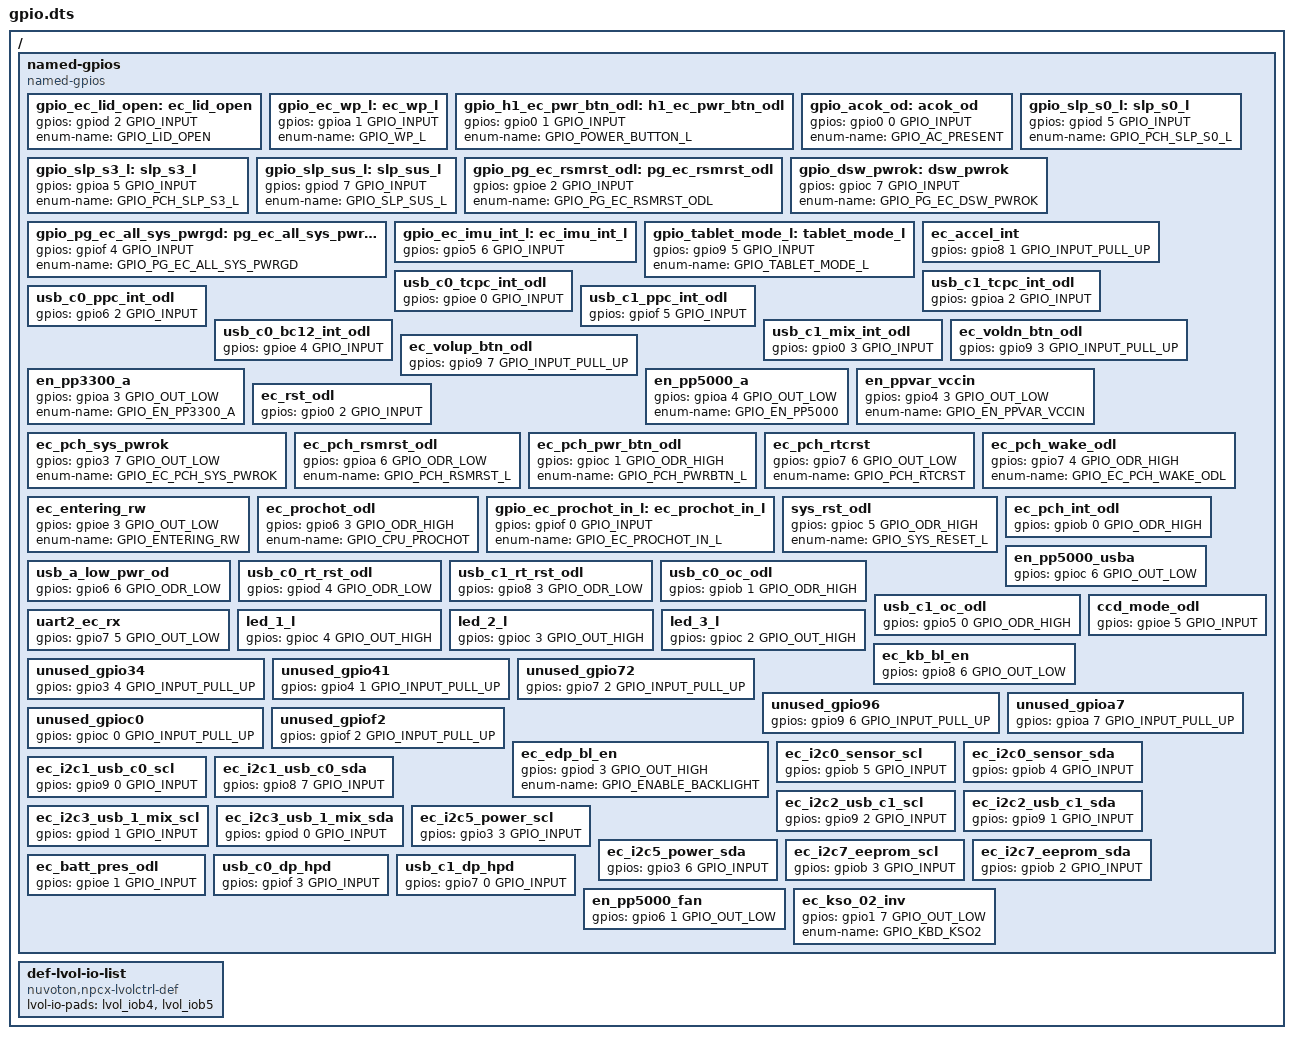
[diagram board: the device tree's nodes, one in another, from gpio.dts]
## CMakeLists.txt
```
# Copyright 2021 The Chromium OS Authors. All rights reserved.
# Use of this source code is governed by a BSD-style license that can be
# found in the LICENSE file.

cmake_minimum_required(VERSION 3.13.1)

find_package(Zephyr REQUIRED HINTS $ENV{ZEPHYR_BASE})
project(delbin)

set(PLATFORM_EC_BOARD "${PLATFORM_EC}/board/delbin" CACHE PATH
  "Path to the platform/ec board directory")
set(PLATFORM_EC_BASEBOARD "${PLATFORM_EC}/baseboard/volteer" CACHE PATH
  "Path to the platform/ec baseboard directory")

# Include board specific header files
zephyr_library_include_directories(
  include
  "${PLATFORM_EC_BASEBOARD}"
  "${PLATFORM_EC_BOARD}")

# Include selected EC source for the baseboard
zephyr_library_sources_ifdef(CONFIG_PLATFORM_EC_POWERSEQ
  "${PLATFORM_EC_BASEBOARD}/power.c")
```

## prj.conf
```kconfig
# Copyright 2021 The Chromium OS Authors. All rights reserved.
# Use of this source code is governed by a BSD-style license that can be
# found in the LICENSE file.

CONFIG_CROS_EC=y
CONFIG_PLATFORM_EC=y
CONFIG_SHIMMED_TASKS=y
CONFIG_I2C=y
CONFIG_PLATFORM_EC_BRINGUP=y

CONFIG_ARM_MPU=y

CONFIG_PLATFORM_EC_VBOOT_EFS2=n

CONFIG_ESPI=y
CONFIG_PLATFORM_EC_ESPI_VW_SLP_S4=y
CONFIG_PLATFORM_EC_ESPI_VW_SLP_S5=y

CONFIG_PLATFORM_EC_EXTPOWER_GPIO=y
CONFIG_PLATFORM_EC_LID_SWITCH=y
CONFIG_PLATFORM_EC_POWER_BUTTON=y

# Power sequencing
CONFIG_AP=y
CONFIG_AP_X86_INTEL_TGL=y
CONFIG_PLATFORM_EC_POWERSEQ=y
CONFIG_PLATFORM_EC_POWERSEQ_RTC_RESET=y
CONFIG_PLATFORM_EC_POWERSEQ_S0IX=y
CONFIG_PLATFORM_EC_POWERSEQ_S4=y
CONFIG_PLATFORM_EC_POWER_SLEEP_FAILURE_DETECTION=y
CONFIG_PLATFORM_EC_THROTTLE_AP=y
CONFIG_PLATFORM_EC_KEYBOARD_COL2_INVERTED=y

# TODO(b/180410072): bringup these features
CONFIG_PLATFORM_EC_BOARD_VERSION_CBI=n
CONFIG_PLATFORM_EC_BOARD_VERSION_GPIO=n
CONFIG_PLATFORM_EC_VBOOT_HASH=n
CONFIG_PLATFORM_EC_VSTORE=n

# Sensors
CONFIG_PLATFORM_EC_MOTIONSENSE=y
CONFIG_PLATFORM_EC_ACCEL_FIFO=y
CONFIG_PLATFORM_EC_ACCEL_INTERRUPTS=y
CONFIG_PLATFORM_EC_DYNAMIC_MOTION_SENSOR_COUNT=y
CONFIG_PLATFORM_EC_GMR_TABLET_MODE=y
CONFIG_PLATFORM_EC_LID_ANGLE=y
CONFIG_PLATFORM_EC_LID_ANGLE_UPDATE=y
CONFIG_PLATFORM_EC_SENSOR_TIGHT_TIMESTAMPS=y
CONFIG_PLATFORM_EC_TABLET_MODE=y
CONFIG_PLATFORM_EC_THERMISTOR=y
CONFIG_PLATFORM_EC_TEMP_SENSOR=y

# Sensor Drivers
CONFIG_PLATFORM_EC_ACCEL_BMA255=y
CONFIG_PLATFORM_EC_ACCELGYRO_BMI260=y
CONFIG_PLATFORM_EC_ACCELGYRO_BMI_COMM_I2C=y

CONFIG_SYSCON=y
```

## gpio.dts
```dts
/* Copyright 2021 The Chromium OS Authors. All rights reserved.
 * Use of this source code is governed by a BSD-style license that can be
 * found in the LICENSE file.
 */

/ {
	named-gpios {
		compatible = "named-gpios";

		gpio_ec_lid_open: ec_lid_open {
			gpios = <&gpiod 2 GPIO_INPUT>;
			enum-name = "GPIO_LID_OPEN";
		};
		gpio_ec_wp_l: ec_wp_l {
			gpios = <&gpioa 1 GPIO_INPUT>;
			enum-name = "GPIO_WP_L";
		};
		gpio_h1_ec_pwr_btn_odl: h1_ec_pwr_btn_odl {
			gpios = <&gpio0 1 GPIO_INPUT>;
			enum-name = "GPIO_POWER_BUTTON_L";
		};
		gpio_acok_od: acok_od {
			gpios = <&gpio0 0 GPIO_INPUT>;
			enum-name = "GPIO_AC_PRESENT";
		};
		gpio_slp_s0_l: slp_s0_l {
			gpios = <&gpiod 5 GPIO_INPUT>;
			enum-name = "GPIO_PCH_SLP_S0_L";
		};
		gpio_slp_s3_l: slp_s3_l {
			gpios = <&gpioa 5 GPIO_INPUT>;
			enum-name = "GPIO_PCH_SLP_S3_L";
		};
		gpio_slp_sus_l: slp_sus_l {
			gpios = <&gpiod 7 GPIO_INPUT>;
			enum-name = "GPIO_SLP_SUS_L";
		};
		gpio_pg_ec_rsmrst_odl: pg_ec_rsmrst_odl {
			gpios = <&gpioe 2 GPIO_INPUT>;
			enum-name = "GPIO_PG_EC_RSMRST_ODL";
		};
		gpio_dsw_pwrok: dsw_pwrok {
			gpios = <&gpioc 7 GPIO_INPUT>;
			enum-name = "GPIO_PG_EC_DSW_PWROK";
		};
		gpio_pg_ec_all_sys_pwrgd: pg_ec_all_sys_pwrgd {
			gpios = <&gpiof 4 GPIO_INPUT>;
			enum-name = "GPIO_PG_EC_ALL_SYS_PWRGD";
		};
		gpio_ec_imu_int_l: ec_imu_int_l {
			gpios = <&gpio5 6 GPIO_INPUT>;
		};
		gpio_tablet_mode_l: tablet_mode_l {
			gpios = <&gpio9 5 GPIO_INPUT>;
			enum-name = "GPIO_TABLET_MODE_L";
		};
		ec_accel_int {
			gpios = <&gpio8 1 GPIO_INPUT_PULL_UP>;
		};
		usb_c0_tcpc_int_odl {
			gpios = <&gpioe 0 GPIO_INPUT>;
		};
		usb_c1_tcpc_int_odl {
			gpios = <&gpioa 2 GPIO_INPUT>;
		};
		usb_c0_ppc_int_odl {
			gpios = <&gpio6 2 GPIO_INPUT>;
		};
		usb_c1_ppc_int_odl {
			gpios = <&gpiof 5 GPIO_INPUT>;
		};
		usb_c0_bc12_int_odl {
			gpios = <&gpioe 4 GPIO_INPUT>;
		};
		usb_c1_mix_int_odl {
			gpios = <&gpio0 3 GPIO_INPUT>;
		};
		ec_voldn_btn_odl {
			gpios = <&gpio9 3 GPIO_INPUT_PULL_UP>;
		};
		ec_volup_btn_odl {
			gpios = <&gpio9 7 GPIO_INPUT_PULL_UP>;
		};
		en_pp3300_a {
			gpios = <&gpioa 3 GPIO_OUT_LOW>;
			enum-name = "GPIO_EN_PP3300_A";
		};
		en_pp5000_a {
			gpios = <&gpioa 4 GPIO_OUT_LOW>;
			enum-name = "GPIO_EN_PP5000";
		};
		en_ppvar_vccin {
			gpios = <&gpio4 3 GPIO_OUT_LOW>;
			enum-name = "GPIO_EN_PPVAR_VCCIN";
		};
		ec_rst_odl {
			gpios = <&gpio0 2 GPIO_INPUT>;
		};
		ec_pch_sys_pwrok {
			gpios = <&gpio3 7 GPIO_OUT_LOW>;
			enum-name = "GPIO_EC_PCH_SYS_PWROK";
		};
		ec_pch_rsmrst_odl {
			gpios = <&gpioa 6 GPIO_ODR_LOW>;
			enum-name = "GPIO_PCH_RSMRST_L";
		};
		ec_pch_pwr_btn_odl {
			gpios = <&gpioc 1 GPIO_ODR_HIGH>;
			enum-name = "GPIO_PCH_PWRBTN_L";
		};
		ec_pch_rtcrst {
			gpios = <&gpio7 6 GPIO_OUT_LOW>;
			enum-name = "GPIO_PCH_RTCRST";
		};
		ec_pch_wake_odl {
			gpios = <&gpio7 4 GPIO_ODR_HIGH>;
			enum-name = "GPIO_EC_PCH_WAKE_ODL";
		};
		ec_entering_rw {
			gpios = <&gpioe 3 GPIO_OUT_LOW>;
			enum-name = "GPIO_ENTERING_RW";
		};
		ec_prochot_odl {
			gpios = <&gpio6 3 GPIO_ODR_HIGH>;
			enum-name = "GPIO_CPU_PROCHOT";
		};
		gpio_ec_prochot_in_l: ec_prochot_in_l {
			gpios = <&gpiof 0 GPIO_INPUT>;
			enum-name = "GPIO_EC_PROCHOT_IN_L";
		};
		sys_rst_odl {
			gpios = <&gpioc 5 GPIO_ODR_HIGH>;
			enum-name = "GPIO_SYS_RESET_L";
		};
		ec_pch_int_odl {
			gpios = <&gpiob 0 GPIO_ODR_HIGH>;
		};
		en_pp5000_usba {
			gpios = <&gpioc 6 GPIO_OUT_LOW>;
		};
		usb_a_low_pwr_od {
			gpios = <&gpio6 6 GPIO_ODR_LOW>;
		};
		usb_c0_rt_rst_odl {
			gpios = <&gpiod 4 GPIO_ODR_LOW>;
		};
		usb_c1_rt_rst_odl {
			gpios = <&gpio8 3 GPIO_ODR_LOW>;
		};
		usb_c0_oc_odl {
			gpios = <&gpiob 1 GPIO_ODR_HIGH>;
		};
		usb_c1_oc_odl {
			gpios = <&gpio5 0 GPIO_ODR_HIGH>;
		};
		uart2_ec_rx {
			gpios = <&gpio7 5 GPIO_OUT_LOW>;
		};
		led_1_l {
			gpios = <&gpioc 4 GPIO_OUT_HIGH>;
		};
		led_2_l {
			gpios = <&gpioc 3 GPIO_OUT_HIGH>;
		};
		led_3_l {
			gpios = <&gpioc 2 GPIO_OUT_HIGH>;
		};
		ccd_mode_odl {
			gpios = <&gpioe 5 GPIO_INPUT>;
		};
		ec_kb_bl_en {
			gpios = <&gpio8 6 GPIO_OUT_LOW>;
		};
		unused_gpio34 {
			gpios = <&gpio3 4 GPIO_INPUT_PULL_UP>;
		};
		unused_gpio41 {
			gpios = <&gpio4 1 GPIO_INPUT_PULL_UP>;
		};
		unused_gpio72 {
			gpios = <&gpio7 2 GPIO_INPUT_PULL_UP>;
		};
		unused_gpio96 {
			gpios = <&gpio9 6 GPIO_INPUT_PULL_UP>;
		};
		unused_gpioa7 {
			gpios = <&gpioa 7 GPIO_INPUT_PULL_UP>;
		};
		unused_gpioc0 {
			gpios = <&gpioc 0 GPIO_INPUT_PULL_UP>;
		};
		unused_gpiof2 {
			gpios = <&gpiof 2 GPIO_INPUT_PULL_UP>;
		};
		ec_edp_bl_en {
			gpios = <&gpiod 3 GPIO_OUT_HIGH>;
			enum-name = "GPIO_ENABLE_BACKLIGHT";
		};
		ec_i2c0_sensor_scl {
			gpios = <&gpiob 5 GPIO_INPUT>;
		};
		ec_i2c0_sensor_sda {
			gpios = <&gpiob 4 GPIO_INPUT>;
		};
		ec_i2c1_usb_c0_scl {
			gpios = <&gpio9 0 GPIO_INPUT>;
		};
		ec_i2c1_usb_c0_sda {
			gpios = <&gpio8 7 GPIO_INPUT>;
		};
		ec_i2c2_usb_c1_scl {
			gpios = <&gpio9 2 GPIO_INPUT>;
		};
		ec_i2c2_usb_c1_sda {
			gpios = <&gpio9 1 GPIO_INPUT>;
		};
		ec_i2c3_usb_1_mix_scl {
			gpios = <&gpiod 1 GPIO_INPUT>;
		};
		ec_i2c3_usb_1_mix_sda {
			gpios = <&gpiod 0 GPIO_INPUT>;
		};
		ec_i2c5_power_scl {
			gpios = <&gpio3 3 GPIO_INPUT>;
		};
		ec_i2c5_power_sda {
			gpios = <&gpio3 6 GPIO_INPUT>;
		};
		ec_i2c7_eeprom_scl {
			gpios = <&gpiob 3 GPIO_INPUT>;
		};
		ec_i2c7_eeprom_sda {
			gpios = <&gpiob 2 GPIO_INPUT>;
		};
		ec_batt_pres_odl {
			gpios = <&gpioe 1 GPIO_INPUT>;
		};
		usb_c0_dp_hpd {
			gpios = <&gpiof 3 GPIO_INPUT>;
		};
		usb_c1_dp_hpd {
			gpios = <&gpio7 0 GPIO_INPUT>;
		};
		en_pp5000_fan {
			gpios = <&gpio6 1 GPIO_OUT_LOW>;
		};
		ec_kso_02_inv {
			gpios = <&gpio1 7 GPIO_OUT_LOW>;
			enum-name = "GPIO_KBD_KSO2";
		};
	};

	def-lvol-io-list {
		compatible = "nuvoton,npcx-lvolctrl-def";

		/* I2C_SDA0 & SCL0 */
		lvol-io-pads = <&lvol_iob4 &lvol_iob5>;
	};
};
```

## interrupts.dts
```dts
/* Copyright 2022 The Chromium OS Authors. All rights reserved.
 * Use of this source code is governed by a BSD-style license that can be
 * found in the LICENSE file.
 */

/ {
	gpio-interrupts {
		compatible = "cros-ec,gpio-interrupts";

		int_imu: imu {
			irq-pin = <&gpio_ec_imu_int_l>;
			flags = <GPIO_INT_EDGE_FALLING>;
			handler = "bmi260_interrupt";
		};
		int_tablet_mode: tablet_mode {
			irq-pin = <&gpio_tablet_mode_l>;
			flags = <GPIO_INT_EDGE_BOTH>;
			handler = "gmr_tablet_switch_isr";
		};
		int_ac_present: ac_present {
			irq-pin = <&gpio_acok_od>;
			flags = <GPIO_INT_EDGE_BOTH>;
			handler = "extpower_interrupt";
		};
		int_lid_open: lid_open {
			irq-pin = <&gpio_ec_lid_open>;
			flags = <GPIO_INT_EDGE_BOTH>;
			handler = "lid_interrupt";
		};
		int_power_button: power_button {
			irq-pin = <&gpio_h1_ec_pwr_btn_odl>;
			flags = <GPIO_INT_EDGE_BOTH>;
			handler = "power_button_interrupt";
		};
		int_wp: wp {
			irq-pin = <&gpio_ec_wp_l>;
			flags = <GPIO_INT_EDGE_BOTH>;
			handler = "switch_interrupt";
		};
		int_pch_slp_s0: pch_slp_s0 {
			irq-pin = <&gpio_slp_s0_l>;
			flags = <GPIO_INT_EDGE_BOTH>;
			handler = "power_signal_interrupt";
		};
		int_pch_slp_s3: pch_slp_s3 {
			irq-pin = <&gpio_slp_s3_l>;
			flags = <GPIO_INT_EDGE_BOTH>;
			handler = "power_signal_interrupt";
		};
		int_dsw_pwrok: dsw_pwrok {
			irq-pin = <&gpio_dsw_pwrok>;
			flags = <GPIO_INT_EDGE_BOTH>;
			handler = "power_signal_interrupt";
		};
		int_rsmrst: rsmrst {
			irq-pin = <&gpio_pg_ec_rsmrst_odl>;
			flags = <GPIO_INT_EDGE_BOTH>;
			handler = "power_signal_interrupt";
		};
		int_all_sys_pwrgd: all_sys_pwrgd {
			irq-pin = <&gpio_pg_ec_all_sys_pwrgd>;
			flags = <GPIO_INT_EDGE_BOTH>;
			handler = "power_signal_interrupt";
		};
		int_slp_sus: slp_sus {
			irq-pin = <&gpio_slp_sus_l>;
			flags = <GPIO_INT_EDGE_BOTH>;
			handler = "power_signal_interrupt";
		};
		int_prochot_in: prochot_in {
			irq-pin = <&gpio_ec_prochot_in_l>;
			flags = <GPIO_INT_EDGE_BOTH>;
			handler = "throttle_ap_prochot_input_interrupt";
		};
	};
};
```

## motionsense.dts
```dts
/* Copyright 2021 The Chromium OS Authors. All rights reserved.
 * Use of this source code is governed by a BSD-style license that can be
 * found in the LICENSE file.
 */

#include <dt-bindings/motionsense/utils.h>


/ {
	aliases {
		/*
		 * motion sense's <>_INT_EVENT is handled
		 * by alias. Using the alias, each driver creates
		 * its own <>_INT_EVENT.
		 */
		bmi260-int = &base_accel;
	};

	/*
	 * Declare mutexes used by sensor drivers.
	 * A mutex node is used to create an instance of mutex_t.
	 * A mutex node is referenced by a sensor node if the
	 * corresponding sensor driver needs to use the
	 * instance of the mutex.
	 */
	motionsense-mutex {
		compatible = "cros-ec,motionsense-mutex";
		mutex_bma255: bma255-mutex {
			label = "BMA255_MUTEX";
		};

		mutex_bmi260: bmi260-mutex {
			label = "BMI260_MUTEX";
		};
	};

	/* Rotation matrix used by drivers. */
	motionsense-rotation-ref {
		compatible = "cros-ec,motionsense-rotation-ref";
		lid_rot_ref: lid-rotation-ref {
			mat33 = <(-1) 0 0
				 0 (-1) 0
				 0 0 1>;
		};
		base_rot_ref: base-rotation-ref {
			mat33 = <1 0 0
				 0 1 0
				 0 0 1>;
		};
	};

	/*
	 * Driver specific data. A driver-specific data can be shared with
	 * different motion sensors while they are using the same driver.
	 *
	 * If a node's compatible starts with "cros-ec,accelgyro-", it is for
	 * a common structure defined in accelgyro.h.
	 * e.g) compatible = "cros-ec,accelgyro-als-drv-data" is for
	 * "struct als_drv_data_t" in accelgyro.h
	 */
	motionsense-sensor-data {
		bma255_data: bma255-drv-data {
			compatible = "cros-ec,drvdata-bma255";
			status = "okay";
		};

		bmi260_data: bmi260-drv-data {
			compatible = "cros-ec,drvdata-bmi260";
			status = "okay";
		};
	};

	/*
	 * List of motion sensors that creates motion_sensors array.
	 * The label "lid_accel" and "base_accel" are used to indicate
	 * motion sensor IDs for lid angle calculation.
	 */
	motionsense-sensor {
		lid_accel: lid-accel {
			compatible = "cros-ec,bma255";
			status = "okay";

			label = "Lid Accel";
			active-mask = "SENSOR_ACTIVE_S0_S3";
			location = "MOTIONSENSE_LOC_LID";
			mutex = <&mutex_bma255>;
			port = <&i2c_sensor>;
			rot-standard-ref = <&lid_rot_ref>;
			default-range = <2>;
			drv-data = <&bma255_data>;
			i2c-spi-addr-flags = "BMA2x2_I2C_ADDR1_FLAGS";
			configs {
				compatible =
					"cros-ec,motionsense-sensor-config";
				ec-s0 {
					label = "SENSOR_CONFIG_EC_S0";
					odr = <(10000 | ROUND_UP_FLAG)>;
				};
				ec-s3 {
					label = "SENSOR_CONFIG_EC_S3";
					odr = <(10000 | ROUND_UP_FLAG)>;
				};
			};
		};

		base_accel: base-accel {
			compatible = "cros-ec,bmi260-accel";
			status = "okay";

			label = "Base Accel";
			active-mask = "SENSOR_ACTIVE_S0_S3";
			location = "MOTIONSENSE_LOC_BASE";
			mutex = <&mutex_bmi260>;
			port = <&i2c_sensor>;
			rot-standard-ref = <&base_rot_ref>;
			default-range = <4>;
			drv-data = <&bmi260_data>;
			i2c-spi-addr-flags = "BMI260_ADDR0_FLAGS";
			configs {
				compatible =
					"cros-ec,motionsense-sensor-config";
				ec-s0 {
					label = "SENSOR_CONFIG_EC_S0";
					odr = <(10000 | ROUND_UP_FLAG)>;
					ec-rate = <(100 * USEC_PER_MSEC)>;
				};
				ec-s3 {
					label = "SENSOR_CONFIG_EC_S3";
					odr = <(10000 | ROUND_UP_FLAG)>;
					ec-rate = <(100 * USEC_PER_MSEC)>;
				};
			};
		};

		base-gyro {
			compatible = "cros-ec,bmi260-gyro";
			status = "okay";

			label = "Base Gyro";
			active-mask = "SENSOR_ACTIVE_S0_S3";
			location = "MOTIONSENSE_LOC_BASE";
			mutex = <&mutex_bmi260>;
			port = <&i2c_sensor>;
			rot-standard-ref = <&base_rot_ref>;
			default-range = <1000>; /* dps */
			drv-data = <&bmi260_data>;
			i2c-spi-addr-flags = "BMI260_ADDR0_FLAGS";
		};
	};

	motionsense-sensor-info {
		compatible = "cros-ec,motionsense-sensor-info";

		/*
		 * list of GPIO interrupts that have to
		 * be enabled at initial stage
		 */
		sensor-irqs = <&int_imu>;
		/* list of sensors in force mode */
		accel-force-mode-sensors = <&lid_accel>;
	};
};
```

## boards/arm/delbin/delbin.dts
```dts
/* Copyright 2021 The Chromium OS Authors. All rights reserved.
 * Use of this source code is governed by a BSD-style license that can be
 * found in the LICENSE file.
 */

/dts-v1/;

#include <cros/nuvoton/npcx.dtsi>
#include <dt-bindings/gpio_defines.h>
#include <nuvoton/npcx7m6fb.dtsi>

/ {
	model = "Google Delbin EC";

	aliases {
		i2c-0 = &i2c0_0;
		i2c-1 = &i2c1_0;
		i2c-2 = &i2c2_0;
		i2c-3 = &i2c3_0;
		i2c-5 = &i2c5_0;
		i2c-7 = &i2c7_0;
	};

	chosen {
		zephyr,sram = &sram0;
		zephyr,console = &uart1;
		zephyr,shell-uart = &uart1;
		zephyr,flash = &flash0;
	};

	named-i2c-ports {
		compatible = "named-i2c-ports";

		sensor {
			i2c-port = <&i2c0_0>;
			label = "SENSOR";
		};
		usb-c0 {
			i2c-port = <&i2c1_0>;
			label = "USB_C0";
		};
		usb-c1 {
			i2c-port = <&i2c2_0>;
			label = "USB_C1";
		};
		usb1-mix {
			i2c-port = <&i2c3_0>;
			label = "USB_1_MIX";
		};
		power {
			i2c-port = <&i2c5_0>;
			label = "POWER";
		};
		eeprom {
			i2c-port = <&i2c7_0>;
			label = "EEPROM";
		};
	};

	soc {
		cros_kb_raw: cros-kb-raw@400a3000 {
			compatible = "nuvoton,npcx-cros-kb-raw";
			reg = <0x400a3000 0x2000>;
			label = "CROS_KB_RAW_0";
			interrupts = <49 0>;
			clocks = <&pcc NPCX_CLOCK_BUS_APB1 NPCX_PWDWN_CTL1 0>;
			/* No KSO2 (it's inverted and implemented by GPIO.) */
			pinctrl-0 = <&alt7_no_ksi0_sl /* KSI0 PIN31 */
				     &alt7_no_ksi1_sl /* KSI1 PIN30 */
				     &alt7_no_ksi2_sl /* KSI2 PIN27 */
				     &alt7_no_ksi3_sl /* KSI3 PIN26 */
				     &alt7_no_ksi4_sl /* KSI4 PIN25 */
				     &alt7_no_ksi5_sl /* KSI5 PIN24 */
				     &alt7_no_ksi6_sl /* KSI6 PIN23 */
				     &alt7_no_ksi7_sl /* KSI7 PIN22 */
				     &alt8_no_kso00_sl /* KSO00 PIN21 */
				     &alt8_no_kso01_sl /* KSO01 PIN20 */
				     &alt8_no_kso03_sl /* KSO03 PIN16 */
				     &alt8_no_kso04_sl /* KSO04 PIN15 */
				     &alt8_no_kso05_sl /* KSO05 PIN14 */
				     &alt8_no_kso06_sl /* KSO06 PIN13 */
				     &alt8_no_kso07_sl /* KSO07 PIN12 */
				     &alt9_no_kso08_sl /* KSO08 PIN11 */
				     &alt9_no_kso09_sl /* KSO09 PIN10 */
				     &alt9_no_kso10_sl /* KSO10 PIN07 */
				     &alt9_no_kso11_sl /* KSO11 PIN06 */
				     &alt9_no_kso12_sl /* KSO12 PIN05 */
				     &alt9_no_kso13_sl /* KSO13 PIN04 */
				     &alt9_no_kso14_sl /* KSO14 PIN82 */
				     >;
			wui_maps = <&wui_io31 &wui_io30 &wui_io27 &wui_io26
				    &wui_io25 &wui_io24 &wui_io23 &wui_io22>;
			status = "disabled";
		};

		fiu0: cros-flash@40020000 {
			compatible = "nuvoton,npcx-cros-flash";
			reg = <0x40020000 0x2000>;
			clocks = <&pcc NPCX_CLOCK_BUS_APB3 NPCX_PWDWN_CTL1 2>;
			size = <0x80000>;
			label = "FLASH_INTERFACE_UNIT0";
			pinctrl-0 = <>;
		};
	};

	/* Update flash size to 512KB from 196KB since we are using C variant */
	/delete-node/ flash@10090000;
	flash0: flash@10070000 {
		reg = <0x10070000 0x40000>;
	};
};

&uart1 {
	status = "okay";
	current-speed = <115200>;
	pinctrl-0 = <&altc_uart1_sl2>; /* Use UART1_SL2 ie. PIN64.65 */
};

&i2c0_0 {
	status = "okay";
	clock-frequency = <I2C_BITRATE_FAST>;
};

&i2c1_0 {
	status = "okay";
	clock-frequency = <I2C_BITRATE_FAST_PLUS>;
};

&i2c2_0 {
	status = "okay";
	clock-frequency = <I2C_BITRATE_FAST_PLUS>;
};

&i2c3_0 {
	status = "okay";
	clock-frequency = <I2C_BITRATE_STANDARD>;
};

&i2c5_0 {
	status = "okay";
	clock-frequency = <I2C_BITRATE_STANDARD>;
};

&i2c7_0 {
	status = "okay";
	clock-frequency = <I2C_BITRATE_FAST>;
};
```

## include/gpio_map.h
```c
/* Copyright 2021 The Chromium OS Authors. All rights reserved.
 * Use of this source code is governed by a BSD-style license that can be
 * found in the LICENSE file.
 */

#ifndef __ZEPHYR_GPIO_MAP_H
#define __ZEPHYR_GPIO_MAP_H

#include <devicetree.h>
#include <gpio_signal.h>

#define GPIO_PCH_DSW_PWROK	GPIO_UNIMPLEMENTED
#define GPIO_USB_C1_LS_EN	GPIO_UNIMPLEMENTED

#endif /* __ZEPHYR_GPIO_MAP_H */
```

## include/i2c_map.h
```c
/* Copyright 2021 The Chromium OS Authors. All rights reserved.
 * Use of this source code is governed by a BSD-style license that can be
 * found in the LICENSE file.
 */

#ifndef __ZEPHYR_I2C_MAP_H
#define __ZEPHYR_I2C_MAP_H

#include <devicetree.h>

#include "i2c/i2c.h"

#define I2C_PORT_ACCEL		I2C_PORT_SENSOR
#define I2C_PORT_SENSOR		NAMED_I2C(sensor)
#define I2C_PORT_USB_C0		NAMED_I2C(usb_c0)
#define I2C_PORT_USB_C1		NAMED_I2C(usb_c1)
#define I2C_PORT_USB_1_MIX	NAMED_I2C(usb1_mix)
#define I2C_PORT_POWER		NAMED_I2C(power)
#define I2C_PORT_EEPROM		NAMED_I2C(eeprom)

#define I2C_ADDR_EEPROM_FLAGS	0x50
#define I2C_PORT_BATTERY	I2C_PORT_POWER
#define I2C_PORT_CHARGER	I2C_PORT_EEPROM

#endif /* __ZEPHYR_I2C_MAP_H */
```

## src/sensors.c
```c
/* Copyright 2021 The Chromium OS Authors. All rights reserved.
 * Use of this source code is governed by a BSD-style license that can be
 * found in the LICENSE file.
 */

#include "chipset.h"
#include "common.h"
#include "keyboard_scan.h"
#include "lid_angle.h"

/* Delbin board specific sensor implementation */

void lid_angle_peripheral_enable(int enable)
{
	int chipset_in_s0 = chipset_in_state(CHIPSET_STATE_ON);

	if (enable) {
		keyboard_scan_enable(1, KB_SCAN_DISABLE_LID_ANGLE);
	} else {
		/*
		 * Ensure that the chipset is off before disabling the keyboard.
		 * When the chipset is on, the EC keeps the keyboard enabled and
		 * the AP decides whether to ignore input devices or not.
		 */
		if (!chipset_in_s0)
			keyboard_scan_enable(0, KB_SCAN_DISABLE_LID_ANGLE);
	}
}
```
